AUTOSAR XML (schema 314)
package /ComponentType
  internal behavior Sa_MtrDrvDiag_InternalBehavior: component=Sa_MtrDrvDiag
    timing event TMT_MtrDrvDiag_Per1: mode-dependency=dependent-on-mode=[SystemState.Mode.DISABLE, SystemState.Mode.OFF], start-on-event=MtrDrvDiag_Per1, period=0.002
    timing event TMT_MtrDrvDiag_Per2: mode-dependency=dependent-on-mode=[SystemState.Mode.OPERATE, SystemState.Mode.WARMINIT], start-on-event=MtrDrvDiag_Per2, period=0.002
    mode switch event MST_MtrDrvDiag_Trns1_0: start-on-event=MtrDrvDiag_Trns1, activation=ENTRY, mode=SystemState.Mode.WARMINIT
    port-api-options:
      enable-take-address=false, indirect-api=false, port=FetDrvReset
      enable-take-address=false, indirect-api=false, port=FETFaultPhase
      enable-take-address=false, indirect-api=false, port=FETFaultType
      enable-take-address=false, indirect-api=false, port=FetFlt1Data
      enable-take-address=false, indirect-api=false, port=FetFlt2Clk
      enable-take-address=false, indirect-api=false, port=GateDriveResetActive
      enable-take-address=false, indirect-api=false, port=IoHwAbPortConfig
      enable-take-address=false, indirect-api=false, port=MtrDrvrInitComplete
      enable-take-address=false, indirect-api=false, port=MtrDrvrInitStart
      enable-take-address=false, indirect-api=false, port=NxtrDiagMgr
      enable-take-address=false, indirect-api=false, port=SystemState
      enable-take-address=false, indirect-api=false, port=SystemTime
    runnable MtrDrvDiag_Per1
      data read access READ_MtrDrvrInitStart_Cnt_lgc: data-element=MtrDrvrInitStart.Cnt_lgc
      4 x data write access:
        WRITE_FETFaultPhase_Cnt_enum: data-element=FETFaultPhase.Cnt_enum
        WRITE_FETFaultType_Cnt_enum: data-element=FETFaultType.Cnt_enum
        WRITE_GateDriveResetActive_Cnt_lgc: data-element=GateDriveResetActive.Cnt_lgc
        WRITE_MtrDrvrInitComplete_Cnt_lgc: data-element=MtrDrvrInitComplete.Cnt_lgc
      11 x sync call, all with timeout=0:
        SC_FetDrvReset_OP_SET: operation=FetDrvReset.OP_SET
        SC_FetFlt1Data_OP_GET: operation=FetFlt1Data.OP_GET
        SC_FetFlt2Clk_OP_GET: operation=FetFlt2Clk.OP_GET
        SC_FetFlt2Clk_OP_SET: operation=FetFlt2Clk.OP_SET
        SC_IoHwAbPortConfig_SetFetFlt2ToOutput: operation=IoHwAbPortConfig.SetFetFlt2ToOutput
        SC_NxtrDiagMgr_GetNTCFailed: operation=NxtrDiagMgr.GetNTCFailed
        SC_NxtrDiagMgr_SetNTCStatus: operation=NxtrDiagMgr.SetNTCStatus
        SC_SystemTime_DtrmnElapsedTime_mS_u16: operation=SystemTime.DtrmnElapsedTime_mS_u16
        SC_SystemTime_DtrmnElapsedTime_uS_u16: operation=SystemTime.DtrmnElapsedTime_uS_u16
        SC_SystemTime_GetSystemTime_mS_u32: operation=SystemTime.GetSystemTime_mS_u32
        SC_SystemTime_GetSystemTime_uS_u32: operation=SystemTime.GetSystemTime_uS_u32
    runnable MtrDrvDiag_Per2
      sync call SC_FetDrvReset_OP_SET: operation=FetDrvReset.OP_SET, timeout=0
    runnable MtrDrvDiag_Trns1
      data write access WRITE_MtrDrvrInitComplete_Cnt_lgc: data-element=MtrDrvrInitComplete.Cnt_lgc
      sync call SC_FetDrvReset_OP_SET: operation=FetDrvReset.OP_SET, timeout=0
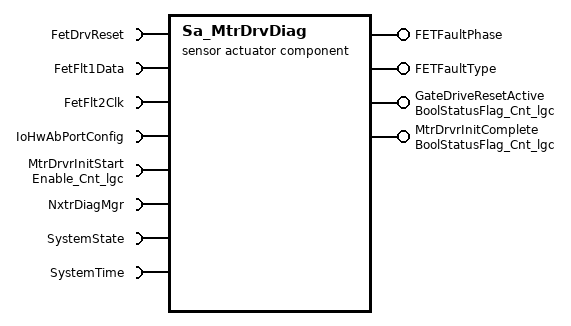
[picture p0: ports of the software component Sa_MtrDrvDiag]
  sensor actuator software component type Sa_MtrDrvDiag
    4 x provide port:
      FETFaultPhase: unqueued-sender-com-spec{data-element=Cnt_enum, can-invalidate=false, init-value=D_FETFAULTPHASEINIT_CNT_ENUM}, provided-interface=FETFaultPhase
      FETFaultType: unqueued-sender-com-spec{data-element=Cnt_enum, can-invalidate=false, init-value=D_FETFAULTTYPEINIT_CNT_ENUM}, provided-interface=FETFaultType
      GateDriveResetActive: unqueued-sender-com-spec{data-element=Cnt_lgc, can-invalidate=false, init-value=D_FALSE_CNT_LGC}, provided-interface=BoolStatusFlag_Cnt_lgc
      MtrDrvrInitComplete: unqueued-sender-com-spec{data-element=Cnt_lgc, can-invalidate=false, init-value=D_FALSE_CNT_LGC}, provided-interface=BoolStatusFlag_Cnt_lgc
    8 x require port:
      FetDrvReset: required-com-specs=[OP_GET, OP_SET], required-interface=FetDrvReset
      FetFlt1Data: client-com-spec=OP_GET, required-interface=FetFlt1Data
      FetFlt2Clk: required-com-specs=[OP_GET, OP_SET], required-interface=FetFlt2Clk
      IoHwAbPortConfig: client-com-spec=SetFetFlt2ToOutput, required-interface=IoHwAbPortConfig
      MtrDrvrInitStart: unqueued-receiver-com-spec{data-element=Cnt_lgc, init-value=D_FALSE_CNT_LGC}, required-interface=Enable_Cnt_lgc
      NxtrDiagMgr: required-com-specs=[GetNTCActive, GetNTCFailed, GetNTCStatus, SetNTCStatus], required-interface=NxtrDiagMgr
      SystemState: required-interface=SystemState
      SystemTime: required-interface=SystemTime
        required-com-specs:
          DtrmnElapsedTime_mS_u16
          DtrmnElapsedTime_mS_u32
          DtrmnElapsedTime_uS_u16
          DtrmnElapsedTime_uS_u32
          GetSystemTime_mS_u32
          GetSystemTime_uS_u32
  swc implementation Sa_MtrDrvDiag_Implementation: behavior=Sa_MtrDrvDiag_InternalBehavior
    code-descriptors:
      code Code: type=SRC
